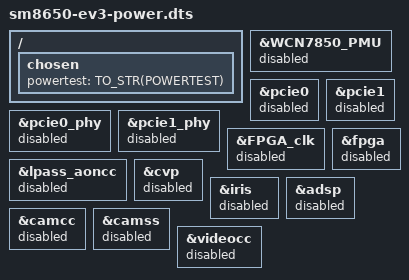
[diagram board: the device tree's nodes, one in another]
/dts-v1/;

#include "sm8650-ev3.dts"

//fw_setenv DTB_QCOM sm8650-ev3-power.dtb


#define POWERTEST 12

#define TO_STR2(x) #x
#define TO_STR(x) TO_STR2(x)

//to check what powertest you are using:
//cat /sys/firmware/devicetree/base/chosen/powertest

/ {
	chosen { 
		powertest = TO_STR(POWERTEST) ;
	};
};


#if POWERTEST == 12

#if 1
//350mW
&WCN7850_PMU {
	status = "disabled";
};

&pcie0 {
	status = "disabled";
};

&pcie0_phy {
	status = "disabled";
};

&pcie1 {
	status = "disabled";
};

&pcie1_phy {
	status = "disabled";
};
#endif


#if 1
//about 150-200mW
&FPGA_clk {
	status = "disabled";
};

&fpga {
	status = "disabled";
};
#endif


#if 1
//120mW
&lpass_aoncc {
	status = "disabled";
};

&cvp {
	status = "disabled";
};

&iris {
	status = "disabled";
};
#endif


#if 1
//~100mW
/ {
	/delete-node/ vdd-nsp;
	/delete-node/ vdd-nsp2;
};
#endif

#if 1
//100mW
&adsp {
	status = "disabled";
};

&camcc {
	status = "disabled";
};

&camss {
	status = "disabled";
};
#endif

#if 1
//30mW
&videocc {
	status = "disabled";
};
#endif




#endif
